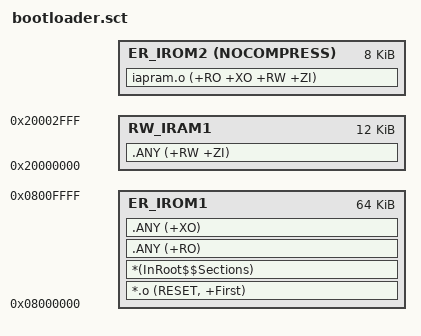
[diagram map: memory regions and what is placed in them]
; *************************************************************
; *** Scatter-Loading Description File generated by uVision ***
; *************************************************************

LR_IROM1 0x08000000 0x00010000  {    ; load region size_region
  ER_IROM1 0x08000000 0x00010000  {  ; load address = execution address
   *.o (RESET, +First)
   *(InRoot$$Sections)
   .ANY (+RO)
   .ANY (+XO)
  }
  RW_IRAM1 0x20000000 0x00003000  {  ; RW data
   .ANY (+RW +ZI)
  }
  ; assign iapram.o running in the followed space in ram
  ER_IROM2 +0 NOCOMPRESS 0x2000 {
   iapram.o (+RO +XO +RW +ZI)
  }
  
}

